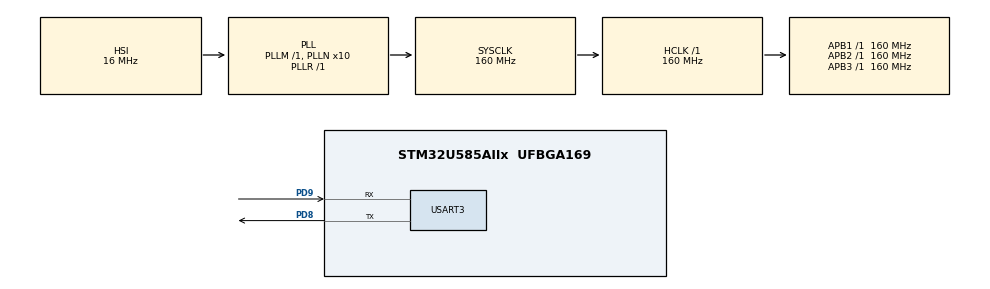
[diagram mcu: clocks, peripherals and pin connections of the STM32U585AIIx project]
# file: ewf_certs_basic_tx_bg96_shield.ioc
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CORTEX_M33_NS.userName=CORTEX_M33
Mcu.Family=STM32U5
Mcu.Name=STM32U585AIIx
Mcu.Package=UFBGA169
NVIC.PriorityGroup=NVIC_PRIORITYGROUP_4
NVIC.TIM6_IRQn=true\:15\:0\:false\:false\:true\:false\:false\:true\:true
NVIC.TimeBase=TIM6_IRQn
NVIC.TimeBaseIP=TIM6
NVIC.USART3_IRQn=true\:0\:0\:false\:false\:true\:false\:true\:true\:true
PA13\ (JTMS/SWDIO).Mode=Trace_Asynchronous_SW
PA13\ (JTMS/SWDIO).Signal=DEBUG_JTMS-SWDIO
PA14\ (JTCK/SWCLK).Mode=Trace_Asynchronous_SW
PA14\ (JTCK/SWCLK).Signal=DEBUG_JTCK-SWCLK
PB3\ (JTDO/TRACESWO).Mode=Trace_Asynchronous_SW
PB3\ (JTDO/TRACESWO).Signal=DEBUG_JTDO-SWO
PD8.Mode=Asynchronous
PD8.Signal=USART3_TX
PD9.Mode=Asynchronous
PD9.Signal=USART3_RX
PWR.PowerMode=PWR_SMPS_SUPPLY
ProjectManager.HeapSize=0x200
ProjectManager.StackSize=0x400
ProjectManager.TargetToolchain=STM32CubeIDE
RCC.ADCFreq_Value=16000000
RCC.AHBFreq_Value=160000000
RCC.APB1Freq_Value=160000000
RCC.APB1TimFreq_Value=160000000
RCC.APB2Freq_Value=160000000
RCC.APB2TimFreq_Value=160000000
RCC.APB3Freq_Value=160000000
RCC.CortexFreq_Value=160000000
RCC.DACCLockSelectionVirtual=RCC_DAC1CLKSOURCE_LSI
RCC.DACCLockSelectionVirtualString=RCC_DAC1CLKSOURCE_LSI
RCC.EPOD_VALUE=16000000
RCC.HCLKFreq_Value=160000000
RCC.HSE_VALUE=16000000
RCC.HSI48_VALUE=48000000
RCC.HSI_VALUE=16000000
RCC.LSE_VALUE=32768
RCC.LSIDIV_VALUE=32000
RCC.MSIClockRange=RCC_MSIRANGE_0
RCC.MSI_VALUE=48000000
RCC.PLL1R=1
RCC.PLLN=10
RCC.PLLSourceVirtual=RCC_PLLSOURCE_HSI
RCC.SPI2CLockSelection=RCC_SPI2CLKSOURCE_PCLK1
RCC.SYSCLKFreq_VALUE=160000000
RCC.SYSCLKSource=RCC_SYSCLKSOURCE_PLLCLK
RCC.USBFreq_Value=48000000
RCC.VCOOutputFreq_Value=160000000
THREADX.AZRTOS_APP_MEM_ALLOCATION_METHOD=1
THREADX.TX_APP_MEM_POOL_SIZE=(1024*2)
USART3.VirtualMode-Asynchronous=VM_ASYNC
VP_ICACHE_VS_ICACHE.Mode=DirectMappedCache
VP_LPBAMQUEUE_VS_QUEUE.Mode=QUEUEMODE
VP_LPBAM_VS_SIG1.Mode=SmartRun
VP_LPBAM_VS_SIG4.Mode=LPDMA1
VP_PWR_VS_DBSignals.Mode=DisableDeadBatterySignals
VP_PWR_VS_LPOM.Mode=PowerOptimisation
VP_PWR_VS_SECSignals.Mode=Security/Privilege
VP_SYS_VS_tim6.Mode=TIM6
VP_THREADX_VS_RTOSJjThreadXJjCoreJjDefault.Mode=Core_Default
board=custom

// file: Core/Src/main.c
/* USER CODE BEGIN Header */
/**
  ******************************************************************************
  * @file           : main.c
  * @brief          : Main program body
  ******************************************************************************
  * @attention
  *
  * Copyright (c) 2022 STMicroelectronics.
  * All rights reserved.
  *
  * This software is licensed under terms that can be found in the LICENSE file
  * in the root directory of this software component.
  * If no LICENSE file comes with this software, it is provided AS-IS.
  *
  ******************************************************************************
  */
/* USER CODE END Header */
#include "main.h"
#include "app_threadx.h"

/* USER CODE BEGIN Includes */

#include "ewf_lib.c"
#include "ewf_platform_threadx.c"
#include "ewf_allocator.c"
#include "ewf_allocator_threadx.c"
#include "ewf_interface.c"
#include "ewf_interface_stm32_uart.c"
#include "ewf_adapter.c"
#include "ewf_adapter_api_control.c"
#include "ewf_adapter_api_info.c"
#include "ewf_adapter_api_tls_basic.c"
#include "ewf_adapter_api_mqtt_basic.c"
#include "ewf_adapter_api_tcp.c"
#include "ewf_adapter_api_udp.c"
#include "ewf_adapter_api_modem.c"
#include "ewf_adapter_api_modem_general.c"
#include "ewf_adapter_api_modem_network_service.c"
#include "ewf_adapter_api_modem_packet_domain.c"
#include "ewf_adapter_api_modem_sim_utility.c"
#include "ewf_adapter_api_modem_sms.c"
#include "ewf_adapter_quectel_bg96.c"

#include "ewf_example.config.h"
#include "ewf_example_certs_basic_quectel_bg96.c"

/* USER CODE END Includes */

/* USER CODE BEGIN PTD */
#if defined ( __GNUC__) && !defined(__clang__)
/* With GCC, small printf (option LD Linker->Libraries->Small printf
   set to 'Yes') calls __io_putchar() */
#define PUTCHAR_PROTOTYPE int __io_putchar(int ch)
#else
#define PUTCHAR_PROTOTYPE int fputc(int ch, FILE *f)
#endif /* __GNUC__ */

/* USER CODE END PTD */

UART_HandleTypeDef huart3;

void SystemClock_Config(void);
static void SystemPower_Config(void);
static void MX_GPIO_Init(void);
static void MX_ICACHE_Init(void);
static void MX_USART3_UART_Init(void);

/* USER CODE BEGIN 0 */

/**
 *  @brief The thread entry point
 */
void thread_entry(ULONG param)
{
    ewf_result result;

    ewf_allocator* message_allocator_ptr = NULL;
    ewf_interface* interface_ptr = NULL;
    ewf_adapter* adapter_ptr = NULL;

    EWF_ALLOCATOR_THREADX_STATIC_DECLARE(message_allocator_ptr, message_allocator, EWF_CONFIG_MESSAGE_ALLOCATOR_BLOCK_COUNT, EWF_CONFIG_MESSAGE_ALLOCATOR_BLOCK_SIZE);
    EWF_INTERFACE_STM32_UART_STATIC_DECLARE(interface_ptr, stm32_uart_port, &huart3);
    EWF_ADAPTER_QUECTEL_BG96_STATIC_DECLARE(adapter_ptr, quectel_bg96, message_allocator_ptr, NULL, interface_ptr);

    // Start the adapter
    if (ewf_result_failed(result = ewf_adapter_start(adapter_ptr)))
    {
        EWF_LOG_ERROR("Failed to start the adapter, ewf_result %d.\n", result);
        exit(result);
    }

    // Set the SIM PIN
    if (ewf_result_failed(result = ewf_adapter_modem_sim_pin_enter(adapter_ptr, EWF_CONFIG_SIM_PIN)))
    {
        EWF_LOG_ERROR("Failed to the SIM PIN, ewf_result %d.\n", result);
        exit(result);
    }

    // Call the certificate provisioning example
    if (ewf_result_failed(result = ewf_example_certs_basic_quectel_bg96(adapter_ptr)))
    {
        EWF_LOG_ERROR("The certificate provisioning example returned and error, ewf_result %d.\n", result);
        exit(result);
    }

    EWF_LOG("Done!\n");

    /* Wait forever  */
    while (1)
    {
        EWF_LOG(".");
        ewf_platform_sleep(EWF_PLATFORM_TICKS_PER_SECOND);
    }
}
/* USER CODE END 0 */

int main(void)
{

  /* MCU Configuration--------------------------------------------------------*/

  /* Reset of all peripherals, Initializes the Flash interface and the Systick. */
  HAL_Init();

  /* Configure the system clock */
  SystemClock_Config();

  /* Configure the System Power */
  SystemPower_Config();

  /* Initialize all configured peripherals */
  MX_GPIO_Init();
  MX_ICACHE_Init();
  MX_USART3_UART_Init();

  MX_ThreadX_Init();

  /* We should never get here as control is now taken by the scheduler */
  /* Infinite loop */
  while (1)
  {

  }
}

void SystemClock_Config(void)
{
  RCC_OscInitTypeDef RCC_OscInitStruct = {0};
  RCC_ClkInitTypeDef RCC_ClkInitStruct = {0};

  /** Configure the main internal regulator output voltage
  */
  if (HAL_PWREx_ControlVoltageScaling(PWR_REGULATOR_VOLTAGE_SCALE1) != HAL_OK)
  {
    Error_Handler();
  }

  /** Initializes the CPU, AHB and APB buses clocks
  */
  RCC_OscInitStruct.OscillatorType = RCC_OSCILLATORTYPE_HSI;
  RCC_OscInitStruct.HSIState = RCC_HSI_ON;
  RCC_OscInitStruct.HSICalibrationValue = RCC_HSICALIBRATION_DEFAULT;
  RCC_OscInitStruct.PLL.PLLState = RCC_PLL_ON;
  RCC_OscInitStruct.PLL.PLLSource = RCC_PLLSOURCE_HSI;
  RCC_OscInitStruct.PLL.PLLMBOOST = RCC_PLLMBOOST_DIV1;
  RCC_OscInitStruct.PLL.PLLM = 1;
  RCC_OscInitStruct.PLL.PLLN = 10;
  RCC_OscInitStruct.PLL.PLLP = 2;
  RCC_OscInitStruct.PLL.PLLQ = 2;
  RCC_OscInitStruct.PLL.PLLR = 1;
  RCC_OscInitStruct.PLL.PLLRGE = RCC_PLLVCIRANGE_1;
  RCC_OscInitStruct.PLL.PLLFRACN = 0;
  if (HAL_RCC_OscConfig(&RCC_OscInitStruct) != HAL_OK)
  {
    Error_Handler();
  }

  /** Initializes the CPU, AHB and APB buses clocks
  */
  RCC_ClkInitStruct.ClockType = RCC_CLOCKTYPE_HCLK|RCC_CLOCKTYPE_SYSCLK
                              |RCC_CLOCKTYPE_PCLK1|RCC_CLOCKTYPE_PCLK2
                              |RCC_CLOCKTYPE_PCLK3;
  RCC_ClkInitStruct.SYSCLKSource = RCC_SYSCLKSOURCE_PLLCLK;
  RCC_ClkInitStruct.AHBCLKDivider = RCC_SYSCLK_DIV1;
  RCC_ClkInitStruct.APB1CLKDivider = RCC_HCLK_DIV1;
  RCC_ClkInitStruct.APB2CLKDivider = RCC_HCLK_DIV1;
  RCC_ClkInitStruct.APB3CLKDivider = RCC_HCLK_DIV1;

  if (HAL_RCC_ClockConfig(&RCC_ClkInitStruct, FLASH_LATENCY_4) != HAL_OK)
  {
    Error_Handler();
  }
}

/**
  * @brief Power Configuration
  * @retval None
  */
static void SystemPower_Config(void)
{

  /*
   * Disable the internal Pull-Up in Dead Battery pins of UCPD peripheral
   */
  HAL_PWREx_DisableUCPDDeadBattery();
}

static void MX_ICACHE_Init(void)
{

  /** Enable instruction cache in 1-way (direct mapped cache)
  */
  if (HAL_ICACHE_ConfigAssociativityMode(ICACHE_1WAY) != HAL_OK)
  {
    Error_Handler();
  }
  if (HAL_ICACHE_Enable() != HAL_OK)
  {
    Error_Handler();
  }

}

static void MX_USART3_UART_Init(void)
{

  huart3.Instance = USART3;
  huart3.Init.BaudRate = 115200;
  huart3.Init.WordLength = UART_WORDLENGTH_8B;
  huart3.Init.StopBits = UART_STOPBITS_1;
  huart3.Init.Parity = UART_PARITY_NONE;
  huart3.Init.Mode = UART_MODE_TX_RX;
  huart3.Init.HwFlowCtl = UART_HWCONTROL_NONE;
  huart3.Init.OverSampling = UART_OVERSAMPLING_16;
  huart3.Init.OneBitSampling = UART_ONE_BIT_SAMPLE_DISABLE;
  huart3.Init.ClockPrescaler = UART_PRESCALER_DIV1;
  huart3.AdvancedInit.AdvFeatureInit = UART_ADVFEATURE_NO_INIT;
  if (HAL_UART_Init(&huart3) != HAL_OK)
  {
    Error_Handler();
  }
  if (HAL_UARTEx_SetTxFifoThreshold(&huart3, UART_TXFIFO_THRESHOLD_1_8) != HAL_OK)
  {
    Error_Handler();
  }
  if (HAL_UARTEx_SetRxFifoThreshold(&huart3, UART_RXFIFO_THRESHOLD_1_8) != HAL_OK)
  {
    Error_Handler();
  }
  if (HAL_UARTEx_DisableFifoMode(&huart3) != HAL_OK)
  {
    Error_Handler();
  }

}

static void MX_GPIO_Init(void)
{

  /* GPIO Ports Clock Enable */
  __HAL_RCC_GPIOA_CLK_ENABLE();
  __HAL_RCC_GPIOB_CLK_ENABLE();
  __HAL_RCC_GPIOD_CLK_ENABLE();

}

/* USER CODE BEGIN 4 */
/**
* @brief  Retargets the C library printf function to the USART.
* @param  None
* @retval None
*/

PUTCHAR_PROTOTYPE
{
    /* Place your implementation of fputc here */
    /* e.g. write a character to the USART1 and Loop until the end of transmission */
    ITM_SendChar(ch);
    return ch;
}
/* USER CODE END 4 */

void HAL_TIM_PeriodElapsedCallback(TIM_HandleTypeDef *htim)
{
  if (htim->Instance == TIM6) {
    HAL_IncTick();
  }
}

void Error_Handler(void)
{
  __disable_irq();
  while (1)
  {
  }
}
